# RP2040 register map
Vendor: Raspberry Pi; Series: RP; File version: 0.1
CPU: CM0PLUS r0p1, little endian, MPU, no FPU, VTOR, 2 interrupt priority bits, 32 interrupts
Registers are 32-bit, read-write, reset 0x0 unless marked. A register's access mark holds for its fields unless they carry their own. Offsets are from the block's base; [hi:lo] are bit positions; {n}, {i} and the like mark numbered series; 'fields as' and 'values as' point back to an identical list; <NAME> marks a mode.

## PIO0 — Programmable IO block
Base 0x50200000
Same registers: PIO1 0x50300000
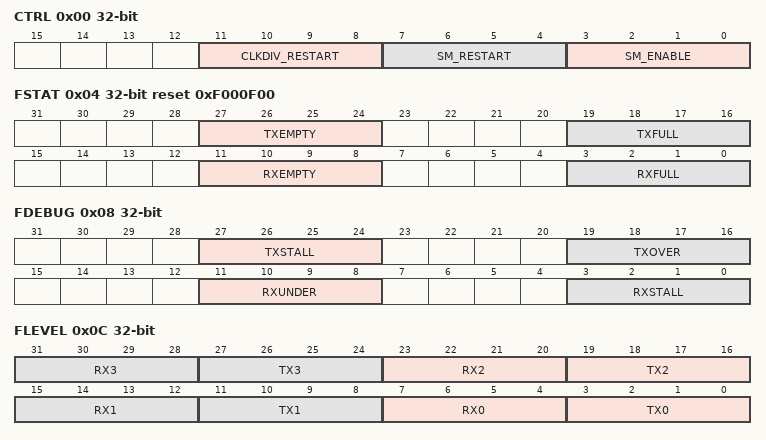
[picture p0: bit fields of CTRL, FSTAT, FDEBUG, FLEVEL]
0x00 CTRL — PIO control register
  [11:8] CLKDIV_RESTART write-1-clears — Restart a state machine's clock divider from an initial phase of 0. Clock dividers are free-running, so once started, their output (including fractional jitter) is completely determined by the integer/fractional divisor configured in SMx_CLKDIV. This means that, if multiple clock dividers with the same divisor are restarted simultaneously, by writing multiple 1 bits to this field, the execution clocks of those state machines will run in precise lockstep. Note that setting/clearing SM_ENABLE does not stop the clock divider from running, so once multiple state machines' clocks are synchronised, it is safe to disable/reenable a state machine, whilst keeping the clock dividers in sync. Note also that CLKDIV_RESTART can be written to whilst the state machine is running, and this is useful to resynchronise clock dividers after the divisors (SMx_CLKDIV) have been changed on-the-fly.
  [7:4] SM_RESTART write-1-clears — Write 1 to instantly clear internal SM state which may be otherwise difficult to access and will affect future execution. Specifically, the following are cleared: input and output shift counters; the contents of the input shift register; the delay counter; the waiting-on-IRQ state; any stalled instruction written to SMx_INSTR or run by OUT/MOV EXEC; any pin write left asserted due to OUT_STICKY. The program counter, the contents of the output shift register and the X/Y scratch registers are not affected.
  [3:0] SM_ENABLE — Enable/disable each of the four state machines by writing 1/0 to each of these four bits. When disabled, a state machine will cease executing instructions, except those written directly to SMx_INSTR by the system. Multiple bits can be set/cleared at once to run/halt multiple state machines simultaneously.
0x04 FSTAT reset 0xF000F00 — FIFO status register
  [27:24] TXEMPTY ro — State machine TX FIFO is empty
  [19:16] TXFULL ro — State machine TX FIFO is full
  [11:8] RXEMPTY ro — State machine RX FIFO is empty
  [3:0] RXFULL ro — State machine RX FIFO is full
0x08 FDEBUG — FIFO debug register
  [27:24] TXSTALL write-1-clears — State machine has stalled on empty TX FIFO during a blocking PULL, or an OUT with autopull enabled. Write 1 to clear.
  [19:16] TXOVER write-1-clears — TX FIFO overflow (i.e. write-on-full by the system) has occurred. Write 1 to clear. Note that write-on-full does not alter the state or contents of the FIFO in any way, but the data that the system attempted to write is dropped, so if this flag is set, your software has quite likely dropped some data on the floor.
  [11:8] RXUNDER write-1-clears — RX FIFO underflow (i.e. read-on-empty by the system) has occurred. Write 1 to clear. Note that read-on-empty does not perturb the state of the FIFO in any way, but the data returned by reading from an empty FIFO is undefined, so this flag generally only becomes set due to some kind of software error.
  [3:0] RXSTALL write-1-clears — State machine has stalled on full RX FIFO during a blocking PUSH, or an IN with autopush enabled. This flag is also set when a nonblocking PUSH to a full FIFO took place, in which case the state machine has dropped data. Write 1 to clear.
0x0C FLEVEL — FIFO levels
  [8n+7:8n+4] RX{n} ro (n=0..3), [8n+3:8n] TX{n} ro (n=0..3)
{0x10+4i} TXF{i} (i=0..3) — Direct write access to the TX FIFO for this state machine. Each write pushes one word to the FIFO. Attempting to write to a full FIFO has no effect on the FIFO state or contents, and sets the sticky FDEBUG_TXOVER error flag for this FIFO.
  [31:0] TXF{i} wo
{0x20+4i} RXF{i} reset not defined (i=0..3) — Direct read access to the RX FIFO for this state machine. Each read pops one word from the FIFO. Attempting to read from an empty FIFO has no effect on the FIFO state, and sets the sticky FDEBUG_RXUNDER error flag for this FIFO. The data returned to the system on a read from an empty FIFO is undefined.
  [31:0] RXF{i} ro read-modifies
0x30 IRQ — State machine IRQ flags register. Write 1 to clear. There are 8 state machine IRQ flags, which can be set, cleared, and waited on by the state machines. There's no fixed association between flags and state machines -- any state machine can use any flag. Any of the 8 flags can be used for timing synchronisation between state machines, using IRQ and WAIT instructions. The lower four of these flags are also routed out to system-level interrupt requests, alongside FIFO status interrupts -- see e.g. IRQ0_INTE.
  [7:0] IRQ write-1-clears
0x34 IRQ_FORCE — Writing a 1 to each of these bits will forcibly assert the corresponding IRQ. Note this is different to the INTF register: writing here affects PIO internal state. INTF just asserts the processor-facing IRQ signal for testing ISRs, and is not visible to the state machines.
  [7:0] IRQ_FORCE wo
0x38 INPUT_SYNC_BYPASS — There is a 2-flipflop synchronizer on each GPIO input, which protects PIO logic from metastabilities. This increases input delay, and for fast synchronous IO (e.g. SPI) these synchronizers may need to be bypassed. Each bit in this register corresponds to one GPIO. 0 -> input is synchronized (default) 1 -> synchronizer is bypassed If in doubt, leave this register as all zeroes.
0x3C DBG_PADOUT — Read to sample the pad output values PIO is currently driving to the GPIOs. On RP2040 there are 30 GPIOs, so the two most significant bits are hardwired to 0.
  [31:0] DBG_PADOUT ro
0x40 DBG_PADOE — Read to sample the pad output enables (direction) PIO is currently driving to the GPIOs. On RP2040 there are 30 GPIOs, so the two most significant bits are hardwired to 0.
  [31:0] DBG_PADOE ro
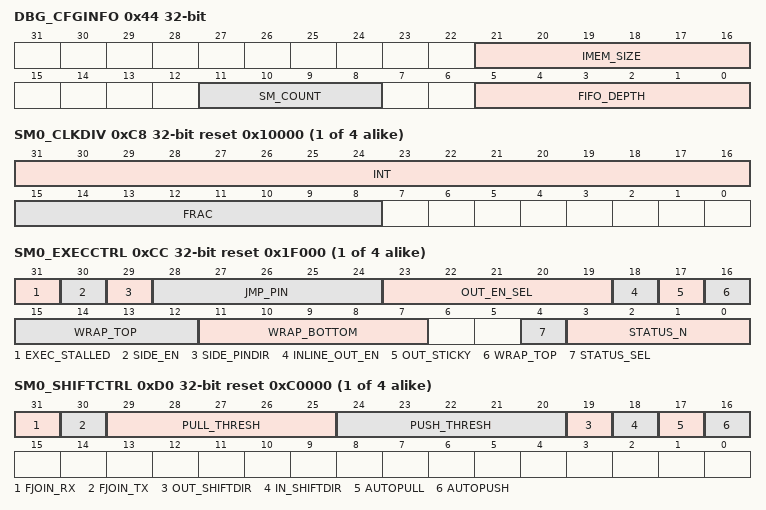
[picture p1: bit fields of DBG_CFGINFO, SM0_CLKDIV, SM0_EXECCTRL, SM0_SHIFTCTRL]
0x44 DBG_CFGINFO — The PIO hardware has some free parameters that may vary between chip products. These should be provided in the chip datasheet, but are also exposed here.
  [21:16] IMEM_SIZE ro — The size of the instruction memory, measured in units of one instruction
  [11:8] SM_COUNT ro — The number of state machines this PIO instance is equipped with.
  [5:0] FIFO_DEPTH ro — The depth of the state machine TX/RX FIFOs, measured in words. Joining fifos via SHIFTCTRL_FJOIN gives one FIFO with double this depth.
{0x48+4i} INSTR_MEM{i} (i=0..31) — Write-only access to instruction memory location {i}
  [15:0] INSTR_MEM{i} wo
{0xC8+0x18*i} SM{i}_CLKDIV reset 0x10000 (i=0..3) — Clock divisor register for state machine {i} Frequency = clock freq / (CLKDIV_INT + CLKDIV_FRAC / 256)
  [31:16] INT — Effective frequency is sysclk/(int + frac/256). Value of 0 is interpreted as 65536. If INT is 0, FRAC must also be 0.
  [15:8] FRAC — Fractional part of clock divisor
{0xCC+0x18*i} SM{i}_EXECCTRL reset 0x1F000 (i=0..3) — Execution/behavioural settings for state machine {i}
  [31] EXEC_STALLED ro — If 1, an instruction written to SMx_INSTR is stalled, and latched by the state machine. Will clear to 0 once this instruction completes.
  [30] SIDE_EN — If 1, the MSB of the Delay/Side-set instruction field is used as side-set enable, rather than a side-set data bit. This allows instructions to perform side-set optionally, rather than on every instruction, but the maximum possible side-set width is reduced from 5 to 4. Note that the value of PINCTRL_SIDESET_COUNT is inclusive of this enable bit.
  [29] SIDE_PINDIR — If 1, side-set data is asserted to pin directions, instead of pin values
  [28:24] JMP_PIN — The GPIO number to use as condition for JMP PIN. Unaffected by input mapping.
  [23:19] OUT_EN_SEL — Which data bit to use for inline OUT enable
  [18] INLINE_OUT_EN — If 1, use a bit of OUT data as an auxiliary write enable When used in conjunction with OUT_STICKY, writes with an enable of 0 will deassert the latest pin write. This can create useful masking/override behaviour due to the priority ordering of state machine pin writes (SM0 < SM1 < ...)
  [17] OUT_STICKY — Continuously assert the most recent OUT/SET to the pins
  [16:12] WRAP_TOP — After reaching this address, execution is wrapped to wrap_bottom. If the instruction is a jump, and the jump condition is true, the jump takes priority.
  [11:7] WRAP_BOTTOM — After reaching wrap_top, execution is wrapped to this address.
  [4] STATUS_SEL — Comparison used for the MOV x, STATUS instruction.
    0=TXLEVEL (All-ones if TX FIFO level < N, otherwise all-zeroes); 1=RXLEVEL (All-ones if RX FIFO level < N, otherwise all-zeroes)
  [3:0] STATUS_N — Comparison level for the MOV x, STATUS instruction
{0xD0+0x18*i} SM{i}_SHIFTCTRL reset 0xC0000 (i=0..3) — Control behaviour of the input/output shift registers for state machine {i}
  [31] FJOIN_RX — When 1, RX FIFO steals the TX FIFO's storage, and becomes twice as deep. TX FIFO is disabled as a result (always reads as both full and empty). FIFOs are flushed when this bit is changed.
  [30] FJOIN_TX — When 1, TX FIFO steals the RX FIFO's storage, and becomes twice as deep. RX FIFO is disabled as a result (always reads as both full and empty). FIFOs are flushed when this bit is changed.
  [29:25] PULL_THRESH — Number of bits shifted out of OSR before autopull, or conditional pull (PULL IFEMPTY), will take place. Write 0 for value of 32.
  [24:20] PUSH_THRESH — Number of bits shifted into ISR before autopush, or conditional push (PUSH IFFULL), will take place. Write 0 for value of 32.
  [19] OUT_SHIFTDIR — 1 = shift out of output shift register to right. 0 = to left.
  [18] IN_SHIFTDIR — 1 = shift input shift register to right (data enters from left). 0 = to left.
  [17] AUTOPULL — Pull automatically when the output shift register is emptied, i.e. on or following an OUT instruction which causes the output shift counter to reach or exceed PULL_THRESH.
  [16] AUTOPUSH — Push automatically when the input shift register is filled, i.e. on an IN instruction which causes the input shift counter to reach or exceed PUSH_THRESH.
{0xD4+0x18*i} SM{i}_ADDR (i=0..3) — Current instruction address of state machine {i}
  [4:0] SM{i}_ADDR ro
{0xD8+0x18*i} SM{i}_INSTR reset not defined (i=0..3) — Read to see the instruction currently addressed by state machine {i}'s program counter Write to execute an instruction immediately (including jumps) and then resume execution.
  [15:0] SM{i}_INSTR
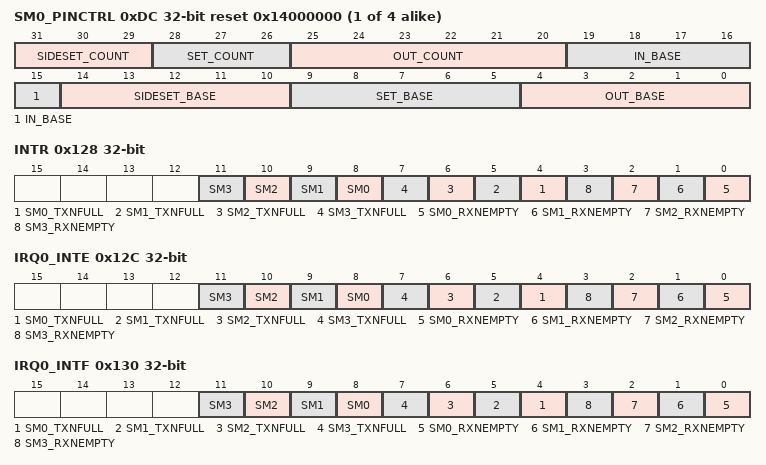
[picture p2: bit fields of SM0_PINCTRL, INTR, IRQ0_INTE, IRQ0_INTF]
{0xDC+0x18*i} SM{i}_PINCTRL reset 0x14000000 (i=0..3) — State machine pin control
  [31:29] SIDESET_COUNT — The number of MSBs of the Delay/Side-set instruction field which are used for side-set. Inclusive of the enable bit, if present. Minimum of 0 (all delay bits, no side-set) and maximum of 5 (all side-set, no delay).
  [28:26] SET_COUNT — The number of pins asserted by a SET. In the range 0 to 5 inclusive.
  [25:20] OUT_COUNT — The number of pins asserted by an OUT PINS, OUT PINDIRS or MOV PINS instruction. In the range 0 to 32 inclusive.
  [19:15] IN_BASE — The pin which is mapped to the least-significant bit of a state machine's IN data bus. Higher-numbered pins are mapped to consecutively more-significant data bits, with a modulo of 32 applied to pin number.
  [14:10] SIDESET_BASE — The lowest-numbered pin that will be affected by a side-set operation. The MSBs of an instruction's side-set/delay field (up to 5, determined by SIDESET_COUNT) are used for side-set data, with the remaining LSBs used for delay. The least-significant bit of the side-set portion is the bit written to this pin, with more-significant bits written to higher-numbered pins.
  [9:5] SET_BASE — The lowest-numbered pin that will be affected by a SET PINS or SET PINDIRS instruction. The data written to this pin is the least-significant bit of the SET data.
  [4:0] OUT_BASE — The lowest-numbered pin that will be affected by an OUT PINS, OUT PINDIRS or MOV PINS instruction. The data written to this pin will always be the least-significant bit of the OUT or MOV data.
0x128 INTR — Raw Interrupts
  [n+8] SM{n} ro (n=0..3), [n+4] SM{n}_TXNFULL ro (n=0..3), [n] SM{n}_RXNEMPTY ro (n=0..3)
0x12C IRQ0_INTE — Interrupt Enable for irq0
  [n+8] SM{n} (n=0..3), [n+4] SM{n}_TXNFULL (n=0..3), [n] SM{n}_RXNEMPTY (n=0..3)
0x130 IRQ0_INTF — Interrupt Force for irq0
  fields as IRQ0_INTE
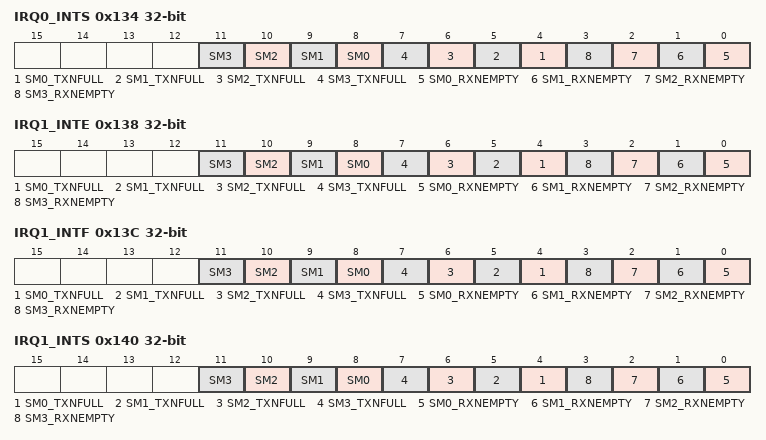
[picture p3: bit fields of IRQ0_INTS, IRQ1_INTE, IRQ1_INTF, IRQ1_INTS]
0x134 IRQ0_INTS — Interrupt status after masking & forcing for irq0
  fields as INTR
0x138 IRQ1_INTE — Interrupt Enable for irq1
  fields as IRQ0_INTE
0x13C IRQ1_INTF — Interrupt Force for irq1
  fields as IRQ0_INTE
0x140 IRQ1_INTS — Interrupt status after masking & forcing for irq1
  fields as INTR
